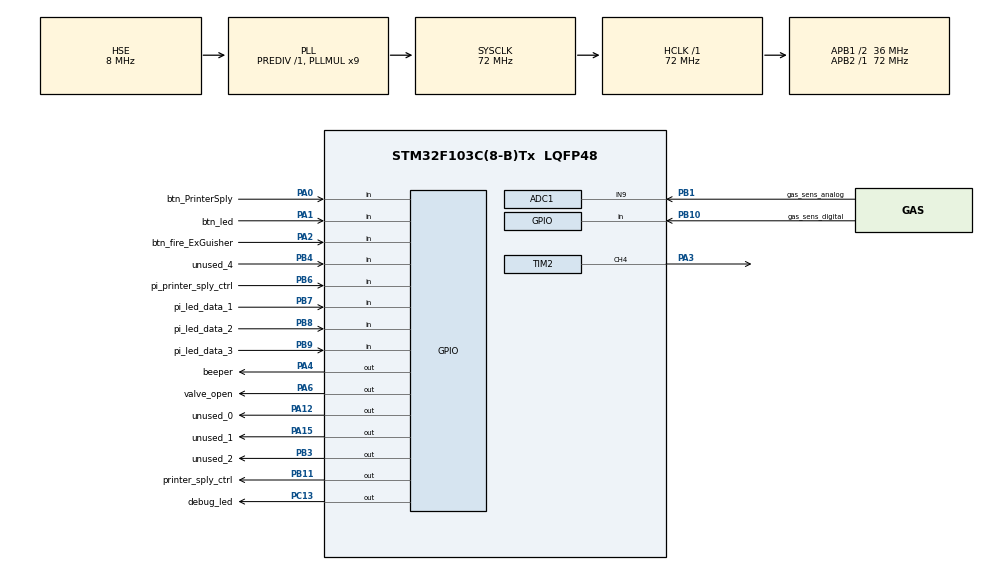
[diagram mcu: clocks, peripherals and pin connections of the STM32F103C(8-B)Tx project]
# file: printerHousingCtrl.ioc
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ADC1.Channel-0\#ChannelRegularConversion=ADC_CHANNEL_9
ADC1.NbrOfConversionFlag=1
ADC1.Rank-0\#ChannelRegularConversion=1
ADC1.SamplingTime-0\#ChannelRegularConversion=ADC_SAMPLETIME_1CYCLE_5
ADC1.master=1
Dma.Request0=TIM2_CH2/CH4
Dma.TIM2_CH2/CH4.0.Direction=DMA_MEMORY_TO_PERIPH
Dma.TIM2_CH2/CH4.0.Instance=DMA1_Channel7
Dma.TIM2_CH2/CH4.0.MemDataAlignment=DMA_MDATAALIGN_BYTE
Dma.TIM2_CH2/CH4.0.MemInc=DMA_MINC_ENABLE
Dma.TIM2_CH2/CH4.0.Mode=DMA_NORMAL
Dma.TIM2_CH2/CH4.0.PeriphDataAlignment=DMA_PDATAALIGN_HALFWORD
Dma.TIM2_CH2/CH4.0.PeriphInc=DMA_PINC_DISABLE
Dma.TIM2_CH2/CH4.0.Priority=DMA_PRIORITY_MEDIUM
Mcu.Family=STM32F1
Mcu.Name=STM32F103C(8-B)Tx
Mcu.Package=LQFP48
NVIC.DMA1_Channel7_IRQn=true\:0\:0\:true\:false\:true\:false\:true\:true
NVIC.PriorityGroup=NVIC_PRIORITYGROUP_4
PA0-WKUP.GPIO_Label=btn_PrinterSply
PA0-WKUP.GPIO_PuPd=GPIO_PULLUP
PA0-WKUP.Signal=GPIO_Input
PA1.GPIO_Label=btn_led
PA1.GPIO_PuPd=GPIO_PULLUP
PA1.Signal=GPIO_Input
PA12.GPIO_Label=unused_0
PA12.Signal=GPIO_Output
PA13.Mode=Serial_Wire
PA13.Signal=SYS_JTMS-SWDIO
PA14.Mode=Serial_Wire
PA14.Signal=SYS_JTCK-SWCLK
PA15.GPIO_Label=unused_1
PA15.Signal=GPIO_Output
PA2.GPIO_Label=btn_fire_ExGuisher
PA2.GPIO_PuPd=GPIO_PULLUP
PA2.Signal=GPIO_Input
PA3.Signal=S_TIM2_CH4
PA4.GPIO_Label=beeper
PA4.Signal=GPIO_Output
PA6.GPIO_Label=valve_open
PA6.Signal=GPIO_Output
PB1.GPIO_Label=gas_sens_analog
PB1.Signal=ADCx_IN9
PB10.GPIO_Label=gas_sens_digital
PB10.GPIO_PuPd=GPIO_PULLUP
PB10.Signal=GPIO_Input
PB11.GPIO_Label=printer_sply_ctrl
PB11.Signal=GPIO_Output
PB3.GPIO_Label=unused_2
PB3.Signal=GPIO_Output
PB4.GPIO_Label=unused_4
PB4.Signal=GPIO_Input
PB6.GPIO_Label=pi_printer_sply_ctrl
PB6.Signal=GPIO_Input
PB7.GPIO_Label=pi_led_data_1
PB7.Signal=GPIO_Input
PB8.GPIO_Label=pi_led_data_2
PB8.Signal=GPIO_Input
PB9.GPIO_Label=pi_led_data_3
PB9.Signal=GPIO_Input
PC13-TAMPER-RTC.GPIO_Label=debug_led
PC13-TAMPER-RTC.Signal=GPIO_Output
PD0-OSC_IN.Mode=HSE-External-Oscillator
PD0-OSC_IN.Signal=RCC_OSC_IN
PD1-OSC_OUT.Mode=HSE-External-Oscillator
PD1-OSC_OUT.Signal=RCC_OSC_OUT
ProjectManager.HeapSize=0x200
ProjectManager.StackSize=0x400
ProjectManager.TargetToolchain=STM32CubeIDE
RCC.ADCPresc=RCC_ADCPCLK2_DIV6
RCC.AHBFreq_Value=72000000
RCC.APB1CLKDivider=RCC_HCLK_DIV2
RCC.APB1Freq_Value=36000000
RCC.APB1TimFreq_Value=72000000
RCC.APB2Freq_Value=72000000
RCC.APB2TimFreq_Value=72000000
RCC.HCLKFreq_Value=72000000
RCC.PLLMUL=RCC_PLL_MUL9
RCC.PLLSourceVirtual=RCC_PLLSOURCE_HSE
RCC.SYSCLKFreq_VALUE=72000000
RCC.SYSCLKSource=RCC_SYSCLKSOURCE_PLLCLK
RCC.USBFreq_Value=72000000
SH.ADCx_IN9.0=ADC1_IN9,IN9
SH.S_TIM2_CH4.0=TIM2_CH4,PWM Generation4 CH4
TIM2.Channel-PWM\ Generation4\ CH4=TIM_CHANNEL_4
TIM2.Period=90-1
VP_TIM2_VS_ClockSourceINT.Mode=Internal
board=custom

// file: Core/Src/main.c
/* USER CODE BEGIN Header */
/**
  ******************************************************************************
  * @file           : main.c
  * @brief          : Main program body
  ******************************************************************************
  * @attention
  *
  * Copyright (c) 2023 STMicroelectronics.
  * All rights reserved.
  *
  * This software is licensed under terms that can be found in the LICENSE file
  * in the root directory of this software component.
  * If no LICENSE file comes with this software, it is provided AS-IS.
  *
  ******************************************************************************
  */
/* USER CODE END Header */
#include "main.h"

/* USER CODE BEGIN Includes */
#include "printerHousingCtrl.h"

/* USER CODE END Includes */

ADC_HandleTypeDef hadc1;

TIM_HandleTypeDef htim2;
DMA_HandleTypeDef hdma_tim2_ch2_ch4;

void SystemClock_Config(void);
static void MX_GPIO_Init(void);
static void MX_DMA_Init(void);
static void MX_ADC1_Init(void);
static void MX_TIM2_Init(void);

int main(void)
{

  /* MCU Configuration--------------------------------------------------------*/

  /* Reset of all peripherals, Initializes the Flash interface and the Systick. */
  HAL_Init();

  /* Configure the system clock */
  SystemClock_Config();

  /* Initialize all configured peripherals */
  MX_GPIO_Init();
  MX_DMA_Init();
  MX_ADC1_Init();
  MX_TIM2_Init();
  /* USER CODE BEGIN 2 */
  printerHousingCtrl_init();
  /* USER CODE END 2 */

  /* Infinite loop */
  while (1)

    /* USER CODE BEGIN 3 */
   printerHousingCtrl_main();
  /* USER CODE END 3 */
}

void SystemClock_Config(void)
{
  RCC_OscInitTypeDef RCC_OscInitStruct = {0};
  RCC_ClkInitTypeDef RCC_ClkInitStruct = {0};
  RCC_PeriphCLKInitTypeDef PeriphClkInit = {0};

  /** Initializes the RCC Oscillators according to the specified parameters
  * in the RCC_OscInitTypeDef structure.
  */
  RCC_OscInitStruct.OscillatorType = RCC_OSCILLATORTYPE_HSE;
  RCC_OscInitStruct.HSEState = RCC_HSE_ON;
  RCC_OscInitStruct.HSEPredivValue = RCC_HSE_PREDIV_DIV1;
  RCC_OscInitStruct.HSIState = RCC_HSI_ON;
  RCC_OscInitStruct.PLL.PLLState = RCC_PLL_ON;
  RCC_OscInitStruct.PLL.PLLSource = RCC_PLLSOURCE_HSE;
  RCC_OscInitStruct.PLL.PLLMUL = RCC_PLL_MUL9;
  if (HAL_RCC_OscConfig(&RCC_OscInitStruct) != HAL_OK)
  {
    Error_Handler();
  }

  /** Initializes the CPU, AHB and APB buses clocks
  */
  RCC_ClkInitStruct.ClockType = RCC_CLOCKTYPE_HCLK|RCC_CLOCKTYPE_SYSCLK
                              |RCC_CLOCKTYPE_PCLK1|RCC_CLOCKTYPE_PCLK2;
  RCC_ClkInitStruct.SYSCLKSource = RCC_SYSCLKSOURCE_PLLCLK;
  RCC_ClkInitStruct.AHBCLKDivider = RCC_SYSCLK_DIV1;
  RCC_ClkInitStruct.APB1CLKDivider = RCC_HCLK_DIV2;
  RCC_ClkInitStruct.APB2CLKDivider = RCC_HCLK_DIV1;

  if (HAL_RCC_ClockConfig(&RCC_ClkInitStruct, FLASH_LATENCY_2) != HAL_OK)
  {
    Error_Handler();
  }
  PeriphClkInit.PeriphClockSelection = RCC_PERIPHCLK_ADC;
  PeriphClkInit.AdcClockSelection = RCC_ADCPCLK2_DIV6;
  if (HAL_RCCEx_PeriphCLKConfig(&PeriphClkInit) != HAL_OK)
  {
    Error_Handler();
  }
}

static void MX_ADC1_Init(void)
{

  ADC_ChannelConfTypeDef sConfig = {0};

  /** Common config
  */
  hadc1.Instance = ADC1;
  hadc1.Init.ScanConvMode = ADC_SCAN_DISABLE;
  hadc1.Init.ContinuousConvMode = DISABLE;
  hadc1.Init.DiscontinuousConvMode = DISABLE;
  hadc1.Init.ExternalTrigConv = ADC_SOFTWARE_START;
  hadc1.Init.DataAlign = ADC_DATAALIGN_RIGHT;
  hadc1.Init.NbrOfConversion = 1;
  if (HAL_ADC_Init(&hadc1) != HAL_OK)
  {
    Error_Handler();
  }

  /** Configure Regular Channel
  */
  sConfig.Channel = ADC_CHANNEL_9;
  sConfig.Rank = ADC_REGULAR_RANK_1;
  sConfig.SamplingTime = ADC_SAMPLETIME_1CYCLE_5;
  if (HAL_ADC_ConfigChannel(&hadc1, &sConfig) != HAL_OK)
  {
    Error_Handler();
  }

}

static void MX_TIM2_Init(void)
{

  TIM_ClockConfigTypeDef sClockSourceConfig = {0};
  TIM_MasterConfigTypeDef sMasterConfig = {0};
  TIM_OC_InitTypeDef sConfigOC = {0};

  htim2.Instance = TIM2;
  htim2.Init.Prescaler = 0;
  htim2.Init.CounterMode = TIM_COUNTERMODE_UP;
  htim2.Init.Period = 90-1;
  htim2.Init.ClockDivision = TIM_CLOCKDIVISION_DIV1;
  htim2.Init.AutoReloadPreload = TIM_AUTORELOAD_PRELOAD_DISABLE;
  if (HAL_TIM_Base_Init(&htim2) != HAL_OK)
  {
    Error_Handler();
  }
  sClockSourceConfig.ClockSource = TIM_CLOCKSOURCE_INTERNAL;
  if (HAL_TIM_ConfigClockSource(&htim2, &sClockSourceConfig) != HAL_OK)
  {
    Error_Handler();
  }
  if (HAL_TIM_PWM_Init(&htim2) != HAL_OK)
  {
    Error_Handler();
  }
  sMasterConfig.MasterOutputTrigger = TIM_TRGO_RESET;
  sMasterConfig.MasterSlaveMode = TIM_MASTERSLAVEMODE_DISABLE;
  if (HAL_TIMEx_MasterConfigSynchronization(&htim2, &sMasterConfig) != HAL_OK)
  {
    Error_Handler();
  }
  sConfigOC.OCMode = TIM_OCMODE_PWM1;
  sConfigOC.Pulse = 0;
  sConfigOC.OCPolarity = TIM_OCPOLARITY_HIGH;
  sConfigOC.OCFastMode = TIM_OCFAST_DISABLE;
  if (HAL_TIM_PWM_ConfigChannel(&htim2, &sConfigOC, TIM_CHANNEL_4) != HAL_OK)
  {
    Error_Handler();
  }
  HAL_TIM_MspPostInit(&htim2);

}

static void MX_DMA_Init(void)
{

  /* DMA controller clock enable */
  __HAL_RCC_DMA1_CLK_ENABLE();

  /* DMA interrupt init */
  /* DMA1_Channel7_IRQn interrupt configuration */
  HAL_NVIC_SetPriority(DMA1_Channel7_IRQn, 0, 0);
  HAL_NVIC_EnableIRQ(DMA1_Channel7_IRQn);

}

static void MX_GPIO_Init(void)
{
  GPIO_InitTypeDef GPIO_InitStruct = {0};

  /* GPIO Ports Clock Enable */
  __HAL_RCC_GPIOC_CLK_ENABLE();
  __HAL_RCC_GPIOD_CLK_ENABLE();
  __HAL_RCC_GPIOA_CLK_ENABLE();
  __HAL_RCC_GPIOB_CLK_ENABLE();

  /*Configure GPIO pin Output Level */
  HAL_GPIO_WritePin(debug_led_GPIO_Port, debug_led_Pin, GPIO_PIN_RESET);

  /*Configure GPIO pin Output Level */
  HAL_GPIO_WritePin(GPIOA, beeper_Pin|valve_open_Pin|unused_0_Pin|unused_1_Pin, GPIO_PIN_RESET);

  /*Configure GPIO pin Output Level */
  HAL_GPIO_WritePin(GPIOB, printer_sply_ctrl_Pin|unused_2_Pin, GPIO_PIN_RESET);

  /*Configure GPIO pin : debug_led_Pin */
  GPIO_InitStruct.Pin = debug_led_Pin;
  GPIO_InitStruct.Mode = GPIO_MODE_OUTPUT_PP;
  GPIO_InitStruct.Pull = GPIO_NOPULL;
  GPIO_InitStruct.Speed = GPIO_SPEED_FREQ_LOW;
  HAL_GPIO_Init(debug_led_GPIO_Port, &GPIO_InitStruct);

  /*Configure GPIO pins : btn_PrinterSply_Pin btn_led_Pin btn_fire_ExGuisher_Pin */
  GPIO_InitStruct.Pin = btn_PrinterSply_Pin|btn_led_Pin|btn_fire_ExGuisher_Pin;
  GPIO_InitStruct.Mode = GPIO_MODE_INPUT;
  GPIO_InitStruct.Pull = GPIO_PULLUP;
  HAL_GPIO_Init(GPIOA, &GPIO_InitStruct);

  /*Configure GPIO pins : beeper_Pin valve_open_Pin unused_0_Pin unused_1_Pin */
  GPIO_InitStruct.Pin = beeper_Pin|valve_open_Pin|unused_0_Pin|unused_1_Pin;
  GPIO_InitStruct.Mode = GPIO_MODE_OUTPUT_PP;
  GPIO_InitStruct.Pull = GPIO_NOPULL;
  GPIO_InitStruct.Speed = GPIO_SPEED_FREQ_LOW;
  HAL_GPIO_Init(GPIOA, &GPIO_InitStruct);

  /*Configure GPIO pin : gas_sens_digital_Pin */
  GPIO_InitStruct.Pin = gas_sens_digital_Pin;
  GPIO_InitStruct.Mode = GPIO_MODE_INPUT;
  GPIO_InitStruct.Pull = GPIO_PULLUP;
  HAL_GPIO_Init(gas_sens_digital_GPIO_Port, &GPIO_InitStruct);

  /*Configure GPIO pins : printer_sply_ctrl_Pin unused_2_Pin */
  GPIO_InitStruct.Pin = printer_sply_ctrl_Pin|unused_2_Pin;
  GPIO_InitStruct.Mode = GPIO_MODE_OUTPUT_PP;
  GPIO_InitStruct.Pull = GPIO_NOPULL;
  GPIO_InitStruct.Speed = GPIO_SPEED_FREQ_LOW;
  HAL_GPIO_Init(GPIOB, &GPIO_InitStruct);

  /*Configure GPIO pins : unused_4_Pin pi_printer_sply_ctrl_Pin pi_led_data_1_Pin pi_led_data_2_Pin
                           pi_led_data_3_Pin */
  GPIO_InitStruct.Pin = unused_4_Pin|pi_printer_sply_ctrl_Pin|pi_led_data_1_Pin|pi_led_data_2_Pin
                          |pi_led_data_3_Pin;
  GPIO_InitStruct.Mode = GPIO_MODE_INPUT;
  GPIO_InitStruct.Pull = GPIO_NOPULL;
  HAL_GPIO_Init(GPIOB, &GPIO_InitStruct);

}

void Error_Handler(void)
{
  __disable_irq();
  while (1)
  {
  }
}
